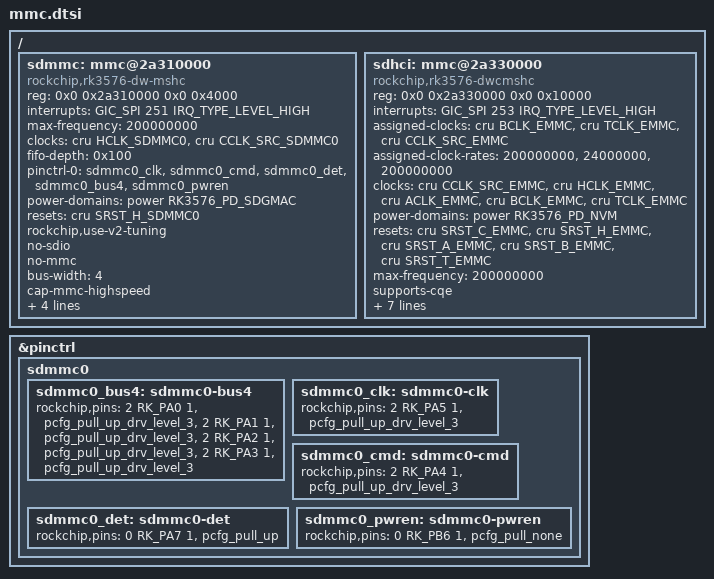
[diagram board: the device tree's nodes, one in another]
/ {
	sdmmc: mmc@2a310000 {
		compatible = "rockchip,rk3576-dw-mshc",
			     "rockchip,rk3288-dw-mshc";
		reg = <0x0 0x2a310000 0x0 0x4000>;
		interrupts = <GIC_SPI 251 IRQ_TYPE_LEVEL_HIGH>;
		max-frequency = <200000000>;
		clocks = <&cru HCLK_SDMMC0>, <&cru CCLK_SRC_SDMMC0>;
		clock-names = "biu", "ciu";
		fifo-depth = <0x100>;
		pinctrl-names = "default";
		pinctrl-0 = <&sdmmc0_clk &sdmmc0_cmd &sdmmc0_det &sdmmc0_bus4 &sdmmc0_pwren>;
		power-domains = <&power RK3576_PD_SDGMAC>;
		resets = <&cru SRST_H_SDMMC0>;
		reset-names = "reset";
		rockchip,use-v2-tuning;
		status = "disabled";
	};

	sdhci: mmc@2a330000 {
		compatible = "rockchip,rk3576-dwcmshc", "rockchip,rk3588-dwcmshc";
		reg = <0x0 0x2a330000 0x0 0x10000>;
		interrupts = <GIC_SPI 253 IRQ_TYPE_LEVEL_HIGH>;
		assigned-clocks = <&cru BCLK_EMMC>, <&cru TCLK_EMMC>, <&cru CCLK_SRC_EMMC>;
		assigned-clock-rates = <200000000>, <24000000>, <200000000>;
		clocks = <&cru CCLK_SRC_EMMC>, <&cru HCLK_EMMC>,
			 <&cru ACLK_EMMC>, <&cru BCLK_EMMC>,
			 <&cru TCLK_EMMC>;
		clock-names = "core", "bus", "axi", "block", "timer";
		power-domains = <&power RK3576_PD_NVM>;
		resets = <&cru SRST_C_EMMC>, <&cru SRST_H_EMMC>,
			 <&cru SRST_A_EMMC>, <&cru SRST_B_EMMC>,
			 <&cru SRST_T_EMMC>;
		reset-names = "core", "bus", "axi", "block", "timer";
		max-frequency = <200000000>;
		supports-cqe;
		status = "disabled";
	};
};


//TF
&sdmmc {
	max-frequency = <200000000>;
	no-sdio;
	no-mmc;
	bus-width = <4>;
	cap-mmc-highspeed;
	cap-sd-highspeed;
	disable-wp;
	sd-uhs-sdr104;
	vqmmc-supply = <&vccio_sd_s0>;
	status = "okay";
};

//emmc
&sdhci {
	bus-width = <8>;
	no-sdio;
	no-sd;
	non-removable;
	max-frequency = <200000000>;
	mmc-hs400-1_8v;
	mmc-hs400-enhanced-strobe;
	full-pwr-cycle-in-suspend;
	status = "okay";
};

&pinctrl {


	sdmmc0 {
		/omit-if-no-ref/
		sdmmc0_bus4: sdmmc0-bus4 {
			rockchip,pins =
				/* sdmmc0_d0 */
				<2 RK_PA0 1 &pcfg_pull_up_drv_level_3>,
				/* sdmmc0_d1 */
				<2 RK_PA1 1 &pcfg_pull_up_drv_level_3>,
				/* sdmmc0_d2 */
				<2 RK_PA2 1 &pcfg_pull_up_drv_level_3>,
				/* sdmmc0_d3 */
				<2 RK_PA3 1 &pcfg_pull_up_drv_level_3>;
		};

		/omit-if-no-ref/
		sdmmc0_clk: sdmmc0-clk {
			rockchip,pins =
				/* sdmmc0_clk */
				<2 RK_PA5 1 &pcfg_pull_up_drv_level_3>;
		};

		/omit-if-no-ref/
		sdmmc0_cmd: sdmmc0-cmd {
			rockchip,pins =
				/* sdmmc0_cmd */
				<2 RK_PA4 1 &pcfg_pull_up_drv_level_3>;
		};

		/omit-if-no-ref/
		sdmmc0_det: sdmmc0-det {
			rockchip,pins =
				/* sdmmc0_detn */
				<0 RK_PA7 1 &pcfg_pull_up>;
		};

		/omit-if-no-ref/
		sdmmc0_pwren: sdmmc0-pwren {
			rockchip,pins =
				/* sdmmc0_pwren */
				<0 RK_PB6 1 &pcfg_pull_none>;
		};
	};

};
